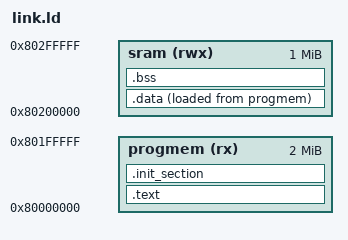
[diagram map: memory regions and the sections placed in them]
/*************************************************************************************************
1.Text an readonly sections are placed in RAM.
2.sdata ,data ,bss ,sbss are placed in RAM(vma) which are copied from RAM(lma) in startup code.
3.Stack is started from end of RAM uptil 1KB.
4.After Stack end,Heap occupies memory region between end of tbss section and stack section. 
***************************************************************************************************/
/****************************************************************************
 * 
 *
 * Licensed to the Apache Software Foundation (ASF) under one or more
 * contributor license agreements.  See the NOTICE file distributed with
 * this work for additional information regarding copyright ownership.  The
 * ASF licenses this file to you under the Apache License, Version 2.0 (the
 * "License"); you may not use this file except in compliance with the
 * License.  You may obtain a copy of the License at
 *
 *   http://www.apache.org/licenses/LICENSE-2.0
 *
 * Unless required by applicable law or agreed to in writing, software
 * distributed under the License is distributed on an "AS IS" BASIS, WITHOUT
 * WARRANTIES OR CONDITIONS OF ANY KIND, either express or implied.  See the
 * License for the specific language governing permissions and limitations
 * under the License.
 *
 ****************************************************************************/

MEMORY
{
 progmem (rx) : ORIGIN = 0x80000000, LENGTH = 2M
  sram (rwx) : ORIGIN = 0x80200000, LENGTH = 1M
}

OUTPUT_ARCH("riscv")

EXTERN(_vectors)
SECTIONS
{
    .text : {
        _stext = ABSOLUTE(.);
        *(.vectors)
        *(.text .text.*)
        *(.fixup)
        *(.gnu.warning)
        *(.rodata .rodata.*)
        *(.gnu.linkonce.t.*)
        *(.glue_7)
        *(.glue_7t)
        *(.got)
        *(.gcc_except_table)
        *(.gnu.linkonce.r.*)
        _etext = ABSOLUTE(.);
    } > progmem

    .init_section : ALIGN(4) {
        _sinit = ABSOLUTE(.);
        KEEP(*(SORT_BY_INIT_PRIORITY(.init_array.*) SORT_BY_INIT_PRIORITY(.ctors.*)))
        KEEP(*(.init_array EXCLUDE_FILE(*crtbegin.o *crtbegin?.o *crtend.o *crtend?.o) .ctors))
        _einit = ABSOLUTE(.);
    } > progmem

    _eronly = ABSOLUTE(.);

    .data : ALIGN(4) {
        _sdata = ABSOLUTE(.);
        *(.data .data.*)
        *(.sdata .sdata.* .sdata2.*)
        *(.gnu.linkonce.d.*)
        *(.gnu.linkonce.s.*)
        CONSTRUCTORS
        . = ALIGN(4);
        _edata = ABSOLUTE(.);
    } > sram AT > progmem

    .bss : ALIGN(4) {
        _sbss = ABSOLUTE(.);
        *(.bss .bss.*)
        *(.sbss .sbss.*)
        *(.gnu.linkonce.b.*)
        *(.gnu.linkonce.sb.*)
        *(COMMON)
        . = ALIGN(32);
        _ebss = ABSOLUTE(.);
    } > sram

    /* Stabs debugging sections. */

    .stab 0 : { *(.stab) }
    .stabstr 0 : { *(.stabstr) }
    .stab.excl 0 : { *(.stab.excl) }
    .stab.exclstr 0 : { *(.stab.exclstr) }
    .stab.index 0 : { *(.stab.index) }
    .stab.indexstr 0 : { *(.stab.indexstr) }
    .comment 0 : { *(.comment) }
    .debug_abbrev 0 : { *(.debug_abbrev) }
    .debug_info 0 : { *(.debug_info) }
    .debug_line 0 : { *(.debug_line) }
    .debug_pubnames 0 : { *(.debug_pubnames) }
    .debug_aranges 0 : { *(.debug_aranges) }
}
